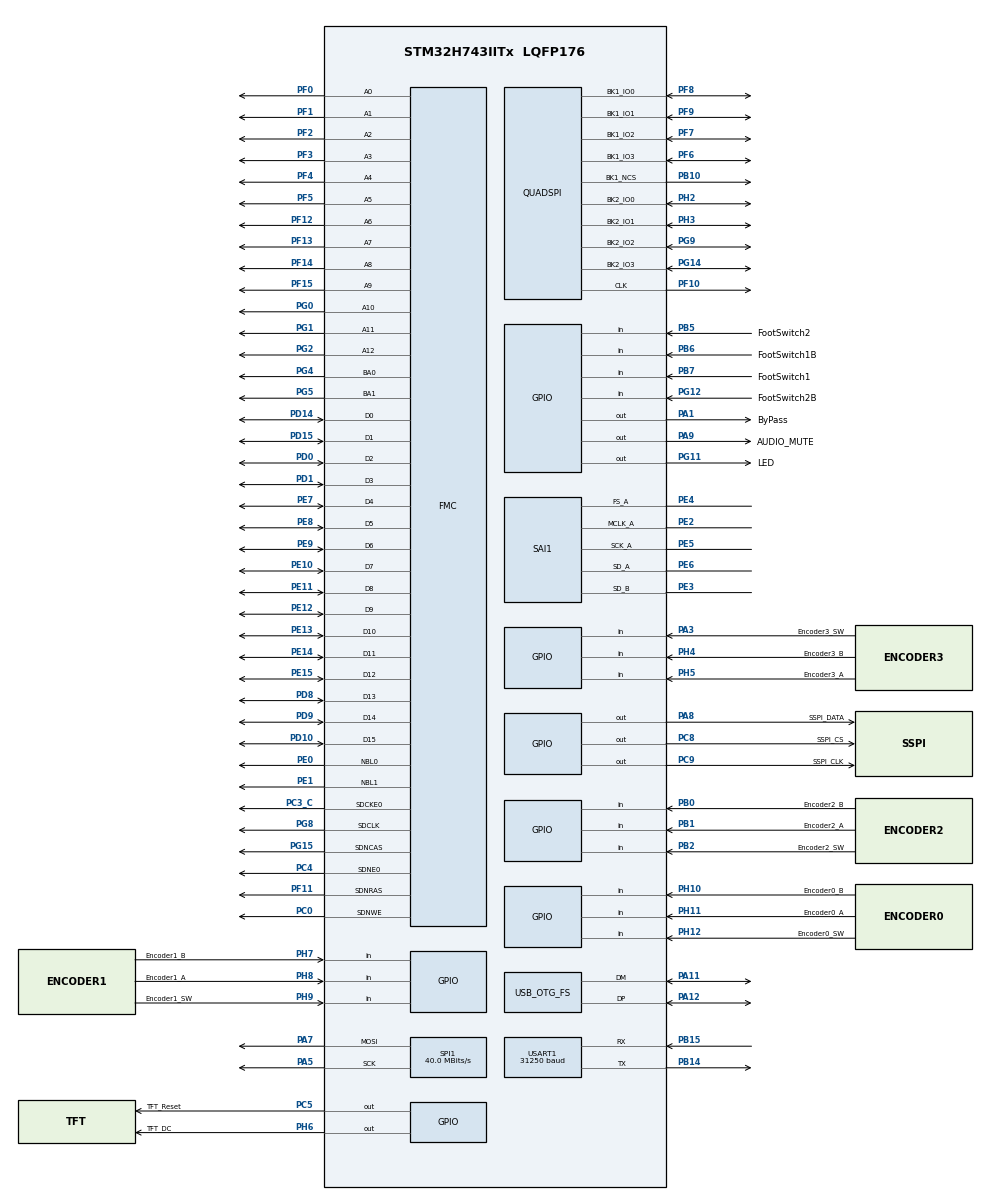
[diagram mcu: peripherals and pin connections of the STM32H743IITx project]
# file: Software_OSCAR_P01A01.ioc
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CORTEX_M7.MPU_Control=__NULL
CORTEX_M7.default_mode_Activation=1
Dma.Request0=SAI1_A
Dma.Request1=SAI1_B
Dma.Request2=SPI1_TX
Dma.Request3=USART1_RX
Dma.SAI1_A.0.Direction=DMA_MEMORY_TO_PERIPH
Dma.SAI1_A.0.EventEnable=DISABLE
Dma.SAI1_A.0.FIFOMode=DMA_FIFOMODE_DISABLE
Dma.SAI1_A.0.Instance=DMA1_Stream0
Dma.SAI1_A.0.MemDataAlignment=DMA_MDATAALIGN_WORD
Dma.SAI1_A.0.MemInc=DMA_MINC_ENABLE
Dma.SAI1_A.0.Mode=DMA_CIRCULAR
Dma.SAI1_A.0.PeriphDataAlignment=DMA_PDATAALIGN_WORD
Dma.SAI1_A.0.PeriphInc=DMA_PINC_DISABLE
Dma.SAI1_A.0.Polarity=HAL_DMAMUX_REQ_GEN_RISING
Dma.SAI1_A.0.Priority=DMA_PRIORITY_HIGH
Dma.SAI1_A.0.RequestNumber=1
Dma.SAI1_A.0.SignalID=NONE
Dma.SAI1_A.0.SyncEnable=DISABLE
Dma.SAI1_A.0.SyncPolarity=HAL_DMAMUX_SYNC_NO_EVENT
Dma.SAI1_A.0.SyncRequestNumber=1
Dma.SAI1_A.0.SyncSignalID=NONE
Dma.SAI1_B.1.Direction=DMA_PERIPH_TO_MEMORY
Dma.SAI1_B.1.EventEnable=DISABLE
Dma.SAI1_B.1.FIFOMode=DMA_FIFOMODE_DISABLE
Dma.SAI1_B.1.Instance=DMA1_Stream1
Dma.SAI1_B.1.MemDataAlignment=DMA_MDATAALIGN_WORD
Dma.SAI1_B.1.MemInc=DMA_MINC_ENABLE
Dma.SAI1_B.1.Mode=DMA_CIRCULAR
Dma.SAI1_B.1.PeriphDataAlignment=DMA_PDATAALIGN_WORD
Dma.SAI1_B.1.PeriphInc=DMA_PINC_DISABLE
Dma.SAI1_B.1.Polarity=HAL_DMAMUX_REQ_GEN_RISING
Dma.SAI1_B.1.Priority=DMA_PRIORITY_HIGH
Dma.SAI1_B.1.RequestNumber=1
Dma.SAI1_B.1.SignalID=NONE
Dma.SAI1_B.1.SyncEnable=DISABLE
Dma.SAI1_B.1.SyncPolarity=HAL_DMAMUX_SYNC_NO_EVENT
Dma.SAI1_B.1.SyncRequestNumber=1
Dma.SAI1_B.1.SyncSignalID=NONE
Dma.SPI1_TX.2.Direction=DMA_MEMORY_TO_PERIPH
Dma.SPI1_TX.2.EventEnable=DISABLE
Dma.SPI1_TX.2.FIFOMode=DMA_FIFOMODE_DISABLE
Dma.SPI1_TX.2.Instance=DMA1_Stream2
Dma.SPI1_TX.2.MemDataAlignment=DMA_MDATAALIGN_BYTE
Dma.SPI1_TX.2.MemInc=DMA_MINC_ENABLE
Dma.SPI1_TX.2.Mode=DMA_NORMAL
Dma.SPI1_TX.2.PeriphDataAlignment=DMA_PDATAALIGN_BYTE
Dma.SPI1_TX.2.PeriphInc=DMA_PINC_DISABLE
Dma.SPI1_TX.2.Polarity=HAL_DMAMUX_REQ_GEN_RISING
Dma.SPI1_TX.2.Priority=DMA_PRIORITY_MEDIUM
Dma.SPI1_TX.2.RequestNumber=1
Dma.SPI1_TX.2.SignalID=NONE
Dma.SPI1_TX.2.SyncEnable=DISABLE
Dma.SPI1_TX.2.SyncPolarity=HAL_DMAMUX_SYNC_NO_EVENT
Dma.SPI1_TX.2.SyncRequestNumber=1
Dma.SPI1_TX.2.SyncSignalID=NONE
Dma.USART1_RX.3.Direction=DMA_PERIPH_TO_MEMORY
Dma.USART1_RX.3.EventEnable=DISABLE
Dma.USART1_RX.3.FIFOMode=DMA_FIFOMODE_DISABLE
Dma.USART1_RX.3.Instance=DMA1_Stream3
Dma.USART1_RX.3.MemDataAlignment=DMA_MDATAALIGN_BYTE
Dma.USART1_RX.3.MemInc=DMA_MINC_ENABLE
Dma.USART1_RX.3.Mode=DMA_CIRCULAR
Dma.USART1_RX.3.PeriphDataAlignment=DMA_PDATAALIGN_BYTE
Dma.USART1_RX.3.PeriphInc=DMA_PINC_DISABLE
Dma.USART1_RX.3.Polarity=HAL_DMAMUX_REQ_GEN_RISING
Dma.USART1_RX.3.Priority=DMA_PRIORITY_LOW
Dma.USART1_RX.3.RequestNumber=1
Dma.USART1_RX.3.SignalID=NONE
Dma.USART1_RX.3.SyncEnable=DISABLE
Dma.USART1_RX.3.SyncPolarity=HAL_DMAMUX_SYNC_NO_EVENT
Dma.USART1_RX.3.SyncRequestNumber=1
Dma.USART1_RX.3.SyncSignalID=NONE
FMC.CASLatency1=FMC_SDRAM_CAS_LATENCY_2
FMC.ColumnBitsNumber1=FMC_SDRAM_COLUMN_BITS_NUM_10
FMC.ExitSelfRefreshDelay1=10
FMC.LoadToActiveDelay1=2
FMC.RCDDelay1=3
FMC.RPDelay1=3
FMC.RPDelay2=3
FMC.ReadBurst1=FMC_SDRAM_RBURST_ENABLE
FMC.ReadBurst2=FMC_SDRAM_RBURST_ENABLE
FMC.ReadPipeDelay1=FMC_SDRAM_RPIPE_DELAY_0
FMC.RowCycleDelay1=10
FMC.RowCycleDelay2=10
FMC.SDClockPeriod1=FMC_SDRAM_CLOCK_PERIOD_2
FMC.SDClockPeriod2=FMC_SDRAM_CLOCK_PERIOD_2
FMC.SelfRefreshTime1=7
FMC.WriteRecoveryTime1=4
Mcu.Family=STM32H7
Mcu.Name=STM32H743IITx
Mcu.Package=LQFP176
NVIC.DMA1_Stream0_IRQn=true\:0\:0\:false\:false\:true\:false\:true\:true
NVIC.DMA1_Stream1_IRQn=true\:0\:0\:false\:false\:true\:false\:true\:true
NVIC.DMA1_Stream2_IRQn=true\:0\:0\:false\:false\:true\:false\:true\:true
NVIC.DMA1_Stream3_IRQn=true\:0\:0\:false\:false\:true\:false\:true\:true
NVIC.OTG_FS_IRQn=true\:0\:0\:false\:false\:true\:false\:true\:true
NVIC.PriorityGroup=NVIC_PRIORITYGROUP_4
NVIC.SPI1_IRQn=true\:0\:0\:false\:false\:true\:false\:true\:true
NVIC.TIM6_DAC_IRQn=true\:0\:0\:false\:false\:true\:true\:true\:true
PA1.GPIO_Label=ByPass
PA1.Signal=GPIO_Output
PA11.Mode=Device_Only
PA11.Signal=USB_OTG_FS_DM
PA12.Mode=Device_Only
PA12.Signal=USB_OTG_FS_DP
PA13\ (JTMS/SWDIO).Mode=Serial_Wire
PA13\ (JTMS/SWDIO).Signal=DEBUG_JTMS-SWDIO
PA14\ (JTCK/SWCLK).Mode=Serial_Wire
PA14\ (JTCK/SWCLK).Signal=DEBUG_JTCK-SWCLK
PA3.GPIO_Label=Encoder3_SW
PA3.GPIO_PuPd=GPIO_PULLUP
PA3.Signal=GPIO_Input
PA5.GPIO_Speed=GPIO_SPEED_FREQ_HIGH
PA5.Mode=TX_Only_Simplex_Unidirect_Master
PA5.Signal=SPI1_SCK
PA7.GPIO_Speed=GPIO_SPEED_FREQ_HIGH
PA7.Mode=TX_Only_Simplex_Unidirect_Master
PA7.Signal=SPI1_MOSI
PA8.GPIO_Label=SSPI_DATA
PA8.GPIO_ModeDefaultOutputPP=GPIO_MODE_OUTPUT_OD
PA8.GPIO_PuPd=GPIO_NOPULL
PA8.GPIO_Speed=GPIO_SPEED_FREQ_HIGH
PA8.Signal=GPIO_Output
PA9.GPIO_Label=AUDIO_MUTE
PA9.GPIO_ModeDefaultOutputPP=GPIO_MODE_OUTPUT_OD
PA9.GPIO_PuPd=GPIO_NOPULL
PA9.Signal=GPIO_Output
PB0.GPIO_Label=Encoder2_B
PB0.GPIO_PuPd=GPIO_PULLUP
PB0.Signal=GPIO_Input
PB1.GPIO_Label=Encoder2_A
PB1.GPIO_PuPd=GPIO_PULLUP
PB1.Signal=GPIO_Input
PB10.GPIO_Speed=GPIO_SPEED_FREQ_VERY_HIGH
PB10.Mode=Enable Chip Select 1 for both banks
PB10.Signal=QUADSPI_BK1_NCS
PB14.Mode=Asynchronous
PB14.Signal=USART1_TX
PB15.Mode=Asynchronous
PB15.Signal=USART1_RX
PB2.GPIO_Label=Encoder2_SW
PB2.GPIO_PuPd=GPIO_PULLUP
PB2.Signal=GPIO_Input
PB5.GPIO_Label=FootSwitch2
PB5.GPIO_PuPd=GPIO_PULLUP
PB5.Signal=GPIO_Input
PB6.GPIO_Label=FootSwitch1B
PB6.GPIO_PuPd=GPIO_PULLUP
PB6.Signal=GPIO_Input
PB7.GPIO_Label=FootSwitch1
PB7.GPIO_PuPd=GPIO_PULLUP
PB7.Signal=GPIO_Input
PC0.Signal=FMC_SDNWE
PC3_C.Mode=SdramChipSelect1_1
PC3_C.Signal=FMC_SDCKE0
PC4.Mode=SdramChipSelect1_1
PC4.Signal=FMC_SDNE0
PC5.GPIO_Label=TFT_Reset
PC5.GPIO_Speed=GPIO_SPEED_FREQ_MEDIUM
PC5.Signal=GPIO_Output
PC8.GPIO_Label=SSPI_CS
PC8.GPIO_ModeDefaultOutputPP=GPIO_MODE_OUTPUT_OD
PC8.GPIO_PuPd=GPIO_NOPULL
PC8.GPIO_Speed=GPIO_SPEED_FREQ_HIGH
PC8.Signal=GPIO_Output
PC9.GPIO_Label=SSPI_CLK
PC9.GPIO_ModeDefaultOutputPP=GPIO_MODE_OUTPUT_OD
PC9.GPIO_PuPd=GPIO_NOPULL
PC9.GPIO_Speed=GPIO_SPEED_FREQ_HIGH
PC9.Signal=GPIO_Output
PD0.Signal=FMC_D2_DA2
PD1.Signal=FMC_D3_DA3
PD10.Signal=FMC_D15_DA15
PD14.Signal=FMC_D0_DA0
PD15.Signal=FMC_D1_DA1
PD8.Signal=FMC_D13_DA13
PD9.Signal=FMC_D14_DA14
PE0.Signal=FMC_NBL0
PE1.Signal=FMC_NBL1
PE10.Signal=FMC_D7_DA7
PE11.Signal=FMC_D8_DA8
PE12.Signal=FMC_D9_DA9
PE13.Signal=FMC_D10_DA10
PE14.Signal=FMC_D11_DA11
PE15.Signal=FMC_D12_DA12
PE2.Mode=SAI_A_MasterWithClock
PE2.Signal=SAI1_MCLK_A
PE3.Mode=SAI_B_SyncSlave
PE3.Signal=SAI1_SD_B
PE4.Mode=SAI_A_MasterWithClock
PE4.Signal=SAI1_FS_A
PE5.Mode=SAI_A_MasterWithClock
PE5.Signal=SAI1_SCK_A
PE6.Mode=SAI_A_MasterWithClock
PE6.Signal=SAI1_SD_A
PE7.Signal=FMC_D4_DA4
PE8.Signal=FMC_D5_DA5
PE9.Signal=FMC_D6_DA6
PF0.Signal=FMC_A0
PF1.Signal=FMC_A1
PF10.GPIO_Speed=GPIO_SPEED_FREQ_VERY_HIGH
PF10.Mode=Dual_Bank
PF10.Signal=QUADSPI_CLK
PF11.Signal=FMC_SDNRAS
PF12.Signal=FMC_A6
PF13.Signal=FMC_A7
PF14.Signal=FMC_A8
PF15.Signal=FMC_A9
PF2.Signal=FMC_A2
PF3.Signal=FMC_A3
PF4.Signal=FMC_A4
PF5.Signal=FMC_A5
PF6.GPIO_Speed=GPIO_SPEED_FREQ_VERY_HIGH
PF6.Mode=Dual_Bank
PF6.Signal=QUADSPI_BK1_IO3
PF7.GPIO_Speed=GPIO_SPEED_FREQ_VERY_HIGH
PF7.Mode=Dual_Bank
PF7.Signal=QUADSPI_BK1_IO2
PF8.GPIO_Speed=GPIO_SPEED_FREQ_VERY_HIGH
PF8.Mode=Dual_Bank
PF8.Signal=QUADSPI_BK1_IO0
PF9.GPIO_Speed=GPIO_SPEED_FREQ_VERY_HIGH
PF9.Mode=Dual_Bank
PF9.Signal=QUADSPI_BK1_IO1
PG0.Signal=FMC_A10
PG1.Signal=FMC_A11
PG11.GPIO_Label=LED
PG11.GPIO_ModeDefaultOutputPP=GPIO_MODE_OUTPUT_OD
PG11.GPIO_PuPd=GPIO_NOPULL
PG11.Signal=GPIO_Output
PG12.GPIO_Label=FootSwitch2B
PG12.GPIO_PuPd=GPIO_PULLUP
PG12.Signal=GPIO_Input
PG14.GPIO_Speed=GPIO_SPEED_FREQ_VERY_HIGH
PG14.Mode=Dual_Bank
PG14.Signal=QUADSPI_BK2_IO3
PG15.Signal=FMC_SDNCAS
PG2.Signal=FMC_A12
PG4.Signal=FMC_A14_BA0
PG5.Signal=FMC_A15_BA1
PG8.Signal=FMC_SDCLK
PG9.GPIO_Speed=GPIO_SPEED_FREQ_VERY_HIGH
PG9.Mode=Dual_Bank
PG9.Signal=QUADSPI_BK2_IO2
PH0-OSC_IN\ (PH0).Mode=HSE-External-Oscillator
PH0-OSC_IN\ (PH0).Signal=RCC_OSC_IN
PH1-OSC_OUT\ (PH1).Mode=HSE-External-Oscillator
PH1-OSC_OUT\ (PH1).Signal=RCC_OSC_OUT
PH10.GPIO_Label=Encoder0_B
PH10.GPIO_PuPd=GPIO_PULLUP
PH10.Signal=GPIO_Input
PH11.GPIO_Label=Encoder0_A
PH11.GPIO_PuPd=GPIO_PULLUP
PH11.Signal=GPIO_Input
PH12.GPIO_Label=Encoder0_SW
PH12.GPIO_PuPd=GPIO_PULLUP
PH12.Signal=GPIO_Input
PH2.GPIO_Speed=GPIO_SPEED_FREQ_VERY_HIGH
PH2.Mode=Dual_Bank
PH2.Signal=QUADSPI_BK2_IO0
PH3.GPIO_Speed=GPIO_SPEED_FREQ_VERY_HIGH
PH3.Mode=Dual_Bank
PH3.Signal=QUADSPI_BK2_IO1
PH4.GPIO_Label=Encoder3_B
PH4.GPIO_PuPd=GPIO_PULLUP
PH4.Signal=GPIO_Input
PH5.GPIO_Label=Encoder3_A
PH5.GPIO_PuPd=GPIO_PULLUP
PH5.Signal=GPIO_Input
PH6.GPIO_Label=TFT_DC
PH6.GPIO_Speed=GPIO_SPEED_FREQ_HIGH
PH6.Signal=GPIO_Output
PH7.GPIO_Label=Encoder1_B
PH7.GPIO_PuPd=GPIO_PULLUP
PH7.Signal=GPIO_Input
PH8.GPIO_Label=Encoder1_A
PH8.GPIO_PuPd=GPIO_PULLUP
PH8.Signal=GPIO_Input
PH9.GPIO_Label=Encoder1_SW
PH9.GPIO_PuPd=GPIO_PULLUP
PH9.Signal=GPIO_Input
ProjectManager.HeapSize=0x8000
ProjectManager.StackSize=0x2000
ProjectManager.TargetToolchain=STM32CubeIDE
QUADSPI.ChipSelectHighTime=QSPI_CS_HIGH_TIME_1_CYCLE
QUADSPI.ClockPrescaler=2
QUADSPI.FlashSize=24
QUADSPI.SampleShifting=QSPI_SAMPLE_SHIFTING_HALFCYCLE
RCC.ADCFreq_Value=185000000
RCC.APB1Freq_Value=120000000
RCC.APB2Freq_Value=120000000
RCC.APB3Freq_Value=120000000
RCC.APB4Freq_Value=120000000
RCC.CortexFreq_Value=480000000
RCC.D1PPRE=RCC_APB3_DIV2
RCC.D2PPRE1=RCC_APB1_DIV2
RCC.D2PPRE2=RCC_APB2_DIV2
RCC.D3PPRE=RCC_APB4_DIV2
RCC.DIVM1=5
RCC.DIVM2=10
RCC.DIVM3=3
RCC.DIVN1=192
RCC.DIVN2=148
RCC.DIVN3=48
RCC.DIVP3=33
RCC.DIVQ1=6
RCC.DIVQ3=3
RCC.DIVR1=8
RCC.FMCCLockSelection=RCC_FMCCLKSOURCE_PLL2
RCC.HCLKFreq_Value=240000000
RCC.HPRE=RCC_HCLK_DIV2
RCC.PLL2FRACN=0
RCC.PLL3FRACN=5411
RCC.PLLSourceVirtual=RCC_PLLSOURCE_HSE
RCC.SAI1CLockSelection=RCC_SAI1CLKSOURCE_PLL3
RCC.SYSCLKFreq_VALUE=480000000
RCC.SYSCLKSource=RCC_SYSCLKSOURCE_PLLCLK
RCC.USBCLockSelection=RCC_USBCLKSOURCE_HSI48
RCC.USBFreq_Value=48000000
SAI1.AudioFrequency-SAI_A_MasterWithClock=SAI_AUDIO_FREQUENCY_48K
SAI1.BasicDataSize-SAI_A_MasterWithClock=SAI_PROTOCOL_DATASIZE_24BIT
SAI1.BasicDataSize-SAI_B_SyncSlave=SAI_PROTOCOL_DATASIZE_24BIT
SAI1.BasicProtocol-SAI_A_MasterWithClock=SAI_I2S_MSBJUSTIFIED
SAI1.BasicProtocol-SAI_B_SyncSlave=SAI_I2S_MSBJUSTIFIED
SAI1.ErrorAudioFreq-SAI_A_MasterWithClock=0.0 %
SAI1.InitProtocol-SAI_A_MasterWithClock=Enable
SAI1.InitProtocol-SAI_B_SyncSlave=Enable
SAI1.Instance-SAI_A_MasterWithClock=SAI$Index_Block_A
SAI1.Instance-SAI_B_SyncSlave=SAI$Index_Block_B
SAI1.MClockEnable-SAI_A_MasterWithClock=SAI_MASTERCLOCK_ENABLE
SAI1.RealAudioFreq-SAI_A_MasterWithClock=48.0 KHz
SAI1.VirtualMode-SAI_A_MasterWithClock=VM_MASTER
SAI1.VirtualMode-SAI_B_SyncSlave=VM_SLAVE
SAI1.VirtualProtocol-SAI_A_BASIC=VM_BASIC_PROTOCOL
SAI1.VirtualProtocol-SAI_B_BASIC=VM_BASIC_PROTOCOL
SH.FMC_A0.0=FMC_A0,13b-sda1
SH.FMC_A1.0=FMC_A1,13b-sda1
SH.FMC_A10.0=FMC_A10,13b-sda1
SH.FMC_A11.0=FMC_A11,13b-sda1
SH.FMC_A12.0=FMC_A12,13b-sda1
SH.FMC_A14_BA0.0=FMC_BA0,FourSdramBanks1
SH.FMC_A15_BA1.0=FMC_BA1,FourSdramBanks1
SH.FMC_A2.0=FMC_A2,13b-sda1
SH.FMC_A3.0=FMC_A3,13b-sda1
SH.FMC_A4.0=FMC_A4,13b-sda1
SH.FMC_A5.0=FMC_A5,13b-sda1
SH.FMC_A6.0=FMC_A6,13b-sda1
SH.FMC_A7.0=FMC_A7,13b-sda1
SH.FMC_A8.0=FMC_A8,13b-sda1
SH.FMC_A9.0=FMC_A9,13b-sda1
SH.FMC_D0_DA0.0=FMC_D0,sd-16b-d1
SH.FMC_D10_DA10.0=FMC_D10,sd-16b-d1
SH.FMC_D11_DA11.0=FMC_D11,sd-16b-d1
SH.FMC_D12_DA12.0=FMC_D12,sd-16b-d1
SH.FMC_D13_DA13.0=FMC_D13,sd-16b-d1
SH.FMC_D14_DA14.0=FMC_D14,sd-16b-d1
SH.FMC_D15_DA15.0=FMC_D15,sd-16b-d1
SH.FMC_D1_DA1.0=FMC_D1,sd-16b-d1
SH.FMC_D2_DA2.0=FMC_D2,sd-16b-d1
SH.FMC_D3_DA3.0=FMC_D3,sd-16b-d1
SH.FMC_D4_DA4.0=FMC_D4,sd-16b-d1
SH.FMC_D5_DA5.0=FMC_D5,sd-16b-d1
SH.FMC_D6_DA6.0=FMC_D6,sd-16b-d1
SH.FMC_D7_DA7.0=FMC_D7,sd-16b-d1
SH.FMC_D8_DA8.0=FMC_D8,sd-16b-d1
SH.FMC_D9_DA9.0=FMC_D9,sd-16b-d1
SH.FMC_NBL0.0=FMC_NBL0,Sd2ByteEnable1
SH.FMC_NBL1.0=FMC_NBL1,Sd2ByteEnable1
SH.FMC_SDCLK.0=FMC_SDCLK,13b-sda1
SH.FMC_SDNCAS.0=FMC_SDNCAS,13b-sda1
SH.FMC_SDNRAS.0=FMC_SDNRAS,13b-sda1
SH.FMC_SDNWE.0=FMC_SDNWE,13b-sda1
SPI1.BaudRatePrescaler=SPI_BAUDRATEPRESCALER_4
SPI1.CLKPhase=SPI_PHASE_2EDGE
SPI1.CLKPolarity=SPI_POLARITY_HIGH
SPI1.CalculateBaudRate=40.0 MBits/s
SPI1.DataSize=SPI_DATASIZE_8BIT
SPI1.Direction=SPI_DIRECTION_2LINES_TXONLY
SPI1.MasterKeepIOState=SPI_MASTER_KEEP_IO_STATE_ENABLE
SPI1.Mode=SPI_MODE_MASTER
SPI1.VirtualType=VM_MASTER
TIM6.AutoReloadPreload=TIM_AUTORELOAD_PRELOAD_ENABLE
TIM6.Period=40-1
TIM6.Prescaler=100-1
USART1.BaudRate=31250
USART1.Mode=MODE_RX
USART1.VirtualMode-Asynchronous=VM_ASYNC
USB_DEVICE.CLASS_NAME_FS=CDC
USB_DEVICE.VirtualMode-CDC_FS=Cdc
USB_DEVICE.VirtualModeFS=Cdc_FS
USB_OTG_FS.VirtualMode=Device_Only
VP_DMA2D_VS_DMA2D.Mode=DMA2D_Activate
VP_MEMORYMAP_VS_MEMORYMAP.Mode=CurAppReg
VP_RNG_VS_RNG.Mode=RNG_Activate
VP_SAI1_VP_$IpInstance_SAIA_SAI_BASIC.Mode=SAI_A_BASIC
VP_SAI1_VP_$IpInstance_SAIB_SAI_BASIC.Mode=SAI_B_BASIC
VP_TIM6_VS_ClockSourceINT.Mode=Enable_Timer
VP_USB_DEVICE_VS_USB_DEVICE_CDC_FS.Mode=CDC_FS
board=custom

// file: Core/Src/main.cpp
/* USER CODE BEGIN Header */
/**
  ******************************************************************************
  * @file           : main.c
  * @brief          : Main program body
  ******************************************************************************
  * @attention
  *
  * Copyright (c) 2026 STMicroelectronics.
  * All rights reserved.
  *
  * This software is licensed under terms that can be found in the LICENSE file
  * in the root directory of this software component.
  * If no LICENSE file comes with this software, it is provided AS-IS.
  *
  ******************************************************************************
  */
/* USER CODE END Header */
#include "main.h"
#include "usb_device.h"

DMA2D_HandleTypeDef hdma2d;

QSPI_HandleTypeDef hqspi;

RNG_HandleTypeDef hrng;

SAI_HandleTypeDef hsai_BlockA1;
SAI_HandleTypeDef hsai_BlockB1;
DMA_HandleTypeDef hdma_sai1_a;
DMA_HandleTypeDef hdma_sai1_b;

SPI_HandleTypeDef hspi1;
DMA_HandleTypeDef hdma_spi1_tx;

TIM_HandleTypeDef htim6;

UART_HandleTypeDef huart1;
DMA_HandleTypeDef hdma_usart1_rx;

SDRAM_HandleTypeDef hsdram1;

void SystemClock_Config(void);
void PeriphCommonClock_Config(void);
static void MX_RNG_Init(void);
/* USER CODE BEGIN PFP */

	// =====** DAD **=================================================================

	extern void HardwareAndCoInitialize();

	// ===** END DAD **===============================================================

/* USER CODE END PFP */

int main(void)
{

  /* USER CODE BEGIN 1 */
	// =====** DAD **=================================================================

	#ifdef USE_RAM
	SCB->VTOR = 0x24000000;
	#endif

	// ===** END DAD **===============================================================

  /* USER CODE END 1 */

  /* MCU Configuration--------------------------------------------------------*/

  /* Reset of all peripherals, Initializes the Flash interface and the Systick. */
  HAL_Init();

  /* USER CODE BEGIN Init */

	// =====** DAD **=================================================================

	// *** LA LIGNE MAGIQUE ***
	// Modifie le registre FPSCR (Floating Point Status and Control Register)
	// Bit 24 (FZ) : Flush-to-zero mode enable
	// Bit 25 (DN) : Default NaN mode enable
	__set_FPSCR(__get_FPSCR() | (1<<24) | (1<<25));

	// ===** END DAD **===============================================================

  /* USER CODE END Init */

  /* Configure the system clock */
  SystemClock_Config();

  /* Configure the peripherals common clocks */
  PeriphCommonClock_Config();

  /* Initialize all configured peripherals */
  MX_GPIO_Init();
  MX_DMA_Init();
  MX_FMC_Init();
  MX_QUADSPI_Init();
  MX_SAI1_Init();
  MX_SPI1_Init();
  MX_USART1_UART_Init();
  MX_TIM6_Init();
  MX_DMA2D_Init();
  MX_USB_DEVICE_Init();
  MX_RNG_Init();
  /* USER CODE BEGIN 2 */

	// =====** DAD **=================================================================

	HardwareAndCoInitialize();

	// ===** END DAD **===============================================================

  /* USER CODE END 2 */

  /* Infinite loop */
  while (1)
  {

  }
}

void SystemClock_Config(void)
{
  RCC_OscInitTypeDef RCC_OscInitStruct = {0};
  RCC_ClkInitTypeDef RCC_ClkInitStruct = {0};

  /** Supply configuration update enable
  */
  HAL_PWREx_ConfigSupply(PWR_LDO_SUPPLY);

  /** Configure the main internal regulator output voltage
  */
  __HAL_PWR_VOLTAGESCALING_CONFIG(PWR_REGULATOR_VOLTAGE_SCALE0);

  while(!__HAL_PWR_GET_FLAG(PWR_FLAG_VOSRDY)) {}

  /** Initializes the RCC Oscillators according to the specified parameters
  * in the RCC_OscInitTypeDef structure.
  */
  RCC_OscInitStruct.OscillatorType = RCC_OSCILLATORTYPE_HSI48|RCC_OSCILLATORTYPE_HSE;
  RCC_OscInitStruct.HSEState = RCC_HSE_ON;
  RCC_OscInitStruct.HSI48State = RCC_HSI48_ON;
  RCC_OscInitStruct.PLL.PLLState = RCC_PLL_ON;
  RCC_OscInitStruct.PLL.PLLSource = RCC_PLLSOURCE_HSE;
  RCC_OscInitStruct.PLL.PLLM = 5;
  RCC_OscInitStruct.PLL.PLLN = 192;
  RCC_OscInitStruct.PLL.PLLP = 2;
  RCC_OscInitStruct.PLL.PLLQ = 6;
  RCC_OscInitStruct.PLL.PLLR = 8;
  RCC_OscInitStruct.PLL.PLLRGE = RCC_PLL1VCIRANGE_2;
  RCC_OscInitStruct.PLL.PLLVCOSEL = RCC_PLL1VCOWIDE;
  RCC_OscInitStruct.PLL.PLLFRACN = 0;
  if (HAL_RCC_OscConfig(&RCC_OscInitStruct) != HAL_OK)
  {
    Error_Handler();
  }

  /** Initializes the CPU, AHB and APB buses clocks
  */
  RCC_ClkInitStruct.ClockType = RCC_CLOCKTYPE_HCLK|RCC_CLOCKTYPE_SYSCLK
                              |RCC_CLOCKTYPE_PCLK1|RCC_CLOCKTYPE_PCLK2
                              |RCC_CLOCKTYPE_D3PCLK1|RCC_CLOCKTYPE_D1PCLK1;
  RCC_ClkInitStruct.SYSCLKSource = RCC_SYSCLKSOURCE_PLLCLK;
  RCC_ClkInitStruct.SYSCLKDivider = RCC_SYSCLK_DIV1;
  RCC_ClkInitStruct.AHBCLKDivider = RCC_HCLK_DIV2;
  RCC_ClkInitStruct.APB3CLKDivider = RCC_APB3_DIV2;
  RCC_ClkInitStruct.APB1CLKDivider = RCC_APB1_DIV2;
  RCC_ClkInitStruct.APB2CLKDivider = RCC_APB2_DIV2;
  RCC_ClkInitStruct.APB4CLKDivider = RCC_APB4_DIV2;

  if (HAL_RCC_ClockConfig(&RCC_ClkInitStruct, FLASH_LATENCY_4) != HAL_OK)
  {
    Error_Handler();
  }
}

void PeriphCommonClock_Config(void)
{
  RCC_PeriphCLKInitTypeDef PeriphClkInitStruct = {0};

  /** Initializes the peripherals clock
  */
  PeriphClkInitStruct.PeriphClockSelection = RCC_PERIPHCLK_SAI1;
  PeriphClkInitStruct.PLL3.PLL3M = 3;
  PeriphClkInitStruct.PLL3.PLL3N = 48;
  PeriphClkInitStruct.PLL3.PLL3P = 33;
  PeriphClkInitStruct.PLL3.PLL3Q = 3;
  PeriphClkInitStruct.PLL3.PLL3R = 2;
  PeriphClkInitStruct.PLL3.PLL3RGE = RCC_PLL3VCIRANGE_3;
  PeriphClkInitStruct.PLL3.PLL3VCOSEL = RCC_PLL3VCOWIDE;
  PeriphClkInitStruct.PLL3.PLL3FRACN = 5411;
  PeriphClkInitStruct.Sai1ClockSelection = RCC_SAI1CLKSOURCE_PLL3;
  if (HAL_RCCEx_PeriphCLKConfig(&PeriphClkInitStruct) != HAL_OK)
  {
    Error_Handler();
  }
}

void MX_DMA2D_Init(void)
{

  hdma2d.Instance = DMA2D;
  hdma2d.Init.Mode = DMA2D_M2M;
  hdma2d.Init.ColorMode = DMA2D_OUTPUT_ARGB8888;
  hdma2d.Init.OutputOffset = 0;
  hdma2d.LayerCfg[1].InputOffset = 0;
  hdma2d.LayerCfg[1].InputColorMode = DMA2D_INPUT_ARGB8888;
  hdma2d.LayerCfg[1].AlphaMode = DMA2D_NO_MODIF_ALPHA;
  hdma2d.LayerCfg[1].InputAlpha = 0;
  hdma2d.LayerCfg[1].AlphaInverted = DMA2D_REGULAR_ALPHA;
  hdma2d.LayerCfg[1].RedBlueSwap = DMA2D_RB_REGULAR;
  hdma2d.LayerCfg[1].ChromaSubSampling = DMA2D_NO_CSS;
  if (HAL_DMA2D_Init(&hdma2d) != HAL_OK)
  {
    Error_Handler();
  }
  if (HAL_DMA2D_ConfigLayer(&hdma2d, 1) != HAL_OK)
  {
    Error_Handler();
  }

}

void MX_QUADSPI_Init(void)
{

  /* QUADSPI parameter configuration*/
  hqspi.Instance = QUADSPI;
  hqspi.Init.ClockPrescaler = 2;
  hqspi.Init.FifoThreshold = 1;
  hqspi.Init.SampleShifting = QSPI_SAMPLE_SHIFTING_HALFCYCLE;
  hqspi.Init.FlashSize = 24;
  hqspi.Init.ChipSelectHighTime = QSPI_CS_HIGH_TIME_1_CYCLE;
  hqspi.Init.ClockMode = QSPI_CLOCK_MODE_0;
  hqspi.Init.DualFlash = QSPI_DUALFLASH_ENABLE;
  if (HAL_QSPI_Init(&hqspi) != HAL_OK)
  {
    Error_Handler();
  }

}

static void MX_RNG_Init(void)
{

  hrng.Instance = RNG;
  hrng.Init.ClockErrorDetection = RNG_CED_ENABLE;
  if (HAL_RNG_Init(&hrng) != HAL_OK)
  {
    Error_Handler();
  }

}

void MX_SAI1_Init(void)
{

  hsai_BlockA1.Instance = SAI1_Block_A;
  hsai_BlockA1.Init.AudioMode = SAI_MODEMASTER_TX;
  hsai_BlockA1.Init.Synchro = SAI_ASYNCHRONOUS;
  hsai_BlockA1.Init.OutputDrive = SAI_OUTPUTDRIVE_DISABLE;
  hsai_BlockA1.Init.NoDivider = SAI_MCK_OVERSAMPLING_DISABLE;
  hsai_BlockA1.Init.MckOverSampling = SAI_MCK_OVERSAMPLING_DISABLE;
  hsai_BlockA1.Init.FIFOThreshold = SAI_FIFOTHRESHOLD_EMPTY;
  hsai_BlockA1.Init.AudioFrequency = SAI_AUDIO_FREQUENCY_48K;
  hsai_BlockA1.Init.SynchroExt = SAI_SYNCEXT_DISABLE;
  hsai_BlockA1.Init.MonoStereoMode = SAI_STEREOMODE;
  hsai_BlockA1.Init.CompandingMode = SAI_NOCOMPANDING;
  hsai_BlockA1.Init.TriState = SAI_OUTPUT_NOTRELEASED;
  if (HAL_SAI_InitProtocol(&hsai_BlockA1, SAI_I2S_MSBJUSTIFIED, SAI_PROTOCOL_DATASIZE_24BIT, 2) != HAL_OK)
  {
    Error_Handler();
  }
  hsai_BlockB1.Instance = SAI1_Block_B;
  hsai_BlockB1.Init.AudioMode = SAI_MODESLAVE_RX;
  hsai_BlockB1.Init.Synchro = SAI_SYNCHRONOUS;
  hsai_BlockB1.Init.OutputDrive = SAI_OUTPUTDRIVE_DISABLE;
  hsai_BlockB1.Init.MckOverSampling = SAI_MCK_OVERSAMPLING_DISABLE;
  hsai_BlockB1.Init.FIFOThreshold = SAI_FIFOTHRESHOLD_EMPTY;
  hsai_BlockB1.Init.SynchroExt = SAI_SYNCEXT_DISABLE;
  hsai_BlockB1.Init.MonoStereoMode = SAI_STEREOMODE;
  hsai_BlockB1.Init.CompandingMode = SAI_NOCOMPANDING;
  hsai_BlockB1.Init.TriState = SAI_OUTPUT_NOTRELEASED;
  if (HAL_SAI_InitProtocol(&hsai_BlockB1, SAI_I2S_MSBJUSTIFIED, SAI_PROTOCOL_DATASIZE_24BIT, 2) != HAL_OK)
  {
    Error_Handler();
  }

}

void MX_SPI1_Init(void)
{

  /* SPI1 parameter configuration*/
  hspi1.Instance = SPI1;
  hspi1.Init.Mode = SPI_MODE_MASTER;
  hspi1.Init.Direction = SPI_DIRECTION_2LINES_TXONLY;
  hspi1.Init.DataSize = SPI_DATASIZE_8BIT;
  hspi1.Init.CLKPolarity = SPI_POLARITY_HIGH;
  hspi1.Init.CLKPhase = SPI_PHASE_2EDGE;
  hspi1.Init.NSS = SPI_NSS_SOFT;
  hspi1.Init.BaudRatePrescaler = SPI_BAUDRATEPRESCALER_4;
  hspi1.Init.FirstBit = SPI_FIRSTBIT_MSB;
  hspi1.Init.TIMode = SPI_TIMODE_DISABLE;
  hspi1.Init.CRCCalculation = SPI_CRCCALCULATION_DISABLE;
  hspi1.Init.CRCPolynomial = 0x0;
  hspi1.Init.NSSPMode = SPI_NSS_PULSE_ENABLE;
  hspi1.Init.NSSPolarity = SPI_NSS_POLARITY_LOW;
  hspi1.Init.FifoThreshold = SPI_FIFO_THRESHOLD_01DATA;
  hspi1.Init.TxCRCInitializationPattern = SPI_CRC_INITIALIZATION_ALL_ZERO_PATTERN;
  hspi1.Init.RxCRCInitializationPattern = SPI_CRC_INITIALIZATION_ALL_ZERO_PATTERN;
  hspi1.Init.MasterSSIdleness = SPI_MASTER_SS_IDLENESS_00CYCLE;
  hspi1.Init.MasterInterDataIdleness = SPI_MASTER_INTERDATA_IDLENESS_00CYCLE;
  hspi1.Init.MasterReceiverAutoSusp = SPI_MASTER_RX_AUTOSUSP_DISABLE;
  hspi1.Init.MasterKeepIOState = SPI_MASTER_KEEP_IO_STATE_ENABLE;
  hspi1.Init.IOSwap = SPI_IO_SWAP_DISABLE;
  if (HAL_SPI_Init(&hspi1) != HAL_OK)
  {
    Error_Handler();
  }

}

void MX_TIM6_Init(void)
{

  TIM_MasterConfigTypeDef sMasterConfig = {0};

  htim6.Instance = TIM6;
  htim6.Init.Prescaler = 100-1;
  htim6.Init.CounterMode = TIM_COUNTERMODE_UP;
  htim6.Init.Period = 40-1;
  htim6.Init.AutoReloadPreload = TIM_AUTORELOAD_PRELOAD_ENABLE;
  if (HAL_TIM_Base_Init(&htim6) != HAL_OK)
  {
    Error_Handler();
  }
  sMasterConfig.MasterOutputTrigger = TIM_TRGO_RESET;
  sMasterConfig.MasterSlaveMode = TIM_MASTERSLAVEMODE_DISABLE;
  if (HAL_TIMEx_MasterConfigSynchronization(&htim6, &sMasterConfig) != HAL_OK)
  {
    Error_Handler();
  }

}

void MX_USART1_UART_Init(void)
{

  huart1.Instance = USART1;
  huart1.Init.BaudRate = 31250;
  huart1.Init.WordLength = UART_WORDLENGTH_8B;
  huart1.Init.StopBits = UART_STOPBITS_1;
  huart1.Init.Parity = UART_PARITY_NONE;
  huart1.Init.Mode = UART_MODE_RX;
  huart1.Init.HwFlowCtl = UART_HWCONTROL_NONE;
  huart1.Init.OverSampling = UART_OVERSAMPLING_16;
  huart1.Init.OneBitSampling = UART_ONE_BIT_SAMPLE_DISABLE;
  huart1.Init.ClockPrescaler = UART_PRESCALER_DIV1;
  huart1.AdvancedInit.AdvFeatureInit = UART_ADVFEATURE_NO_INIT;
  if (HAL_UART_Init(&huart1) != HAL_OK)
  {
    Error_Handler();
  }
  if (HAL_UARTEx_SetTxFifoThreshold(&huart1, UART_TXFIFO_THRESHOLD_1_8) != HAL_OK)
  {
    Error_Handler();
  }
  if (HAL_UARTEx_SetRxFifoThreshold(&huart1, UART_RXFIFO_THRESHOLD_1_8) != HAL_OK)
  {
    Error_Handler();
  }
  if (HAL_UARTEx_DisableFifoMode(&huart1) != HAL_OK)
  {
    Error_Handler();
  }

}

void MX_DMA_Init(void)
{

  /* DMA controller clock enable */
  __HAL_RCC_DMA1_CLK_ENABLE();

  /* DMA interrupt init */
  /* DMA1_Stream0_IRQn interrupt configuration */
  HAL_NVIC_SetPriority(DMA1_Stream0_IRQn, 0, 0);
  HAL_NVIC_EnableIRQ(DMA1_Stream0_IRQn);
  /* DMA1_Stream1_IRQn interrupt configuration */
  HAL_NVIC_SetPriority(DMA1_Stream1_IRQn, 0, 0);
  HAL_NVIC_EnableIRQ(DMA1_Stream1_IRQn);
  /* DMA1_Stream2_IRQn interrupt configuration */
  HAL_NVIC_SetPriority(DMA1_Stream2_IRQn, 0, 0);
  HAL_NVIC_EnableIRQ(DMA1_Stream2_IRQn);
  /* DMA1_Stream3_IRQn interrupt configuration */
  HAL_NVIC_SetPriority(DMA1_Stream3_IRQn, 0, 0);
  HAL_NVIC_EnableIRQ(DMA1_Stream3_IRQn);

}

/* FMC initialization function */
void MX_FMC_Init(void)
{

  FMC_SDRAM_TimingTypeDef SdramTiming = {0};

  /** Perform the SDRAM1 memory initialization sequence
  */
  hsdram1.Instance = FMC_SDRAM_DEVICE;
  /* hsdram1.Init */
  hsdram1.Init.SDBank = FMC_SDRAM_BANK1;
  hsdram1.Init.ColumnBitsNumber = FMC_SDRAM_COLUMN_BITS_NUM_10;
  hsdram1.Init.RowBitsNumber = FMC_SDRAM_ROW_BITS_NUM_13;
  hsdram1.Init.MemoryDataWidth = FMC_SDRAM_MEM_BUS_WIDTH_16;
  hsdram1.Init.InternalBankNumber = FMC_SDRAM_INTERN_BANKS_NUM_4;
  hsdram1.Init.CASLatency = FMC_SDRAM_CAS_LATENCY_2;
  hsdram1.Init.WriteProtection = FMC_SDRAM_WRITE_PROTECTION_DISABLE;
  hsdram1.Init.SDClockPeriod = FMC_SDRAM_CLOCK_PERIOD_2;
  hsdram1.Init.ReadBurst = FMC_SDRAM_RBURST_ENABLE;
  hsdram1.Init.ReadPipeDelay = FMC_SDRAM_RPIPE_DELAY_0;
  /* SdramTiming */
  SdramTiming.LoadToActiveDelay = 2;
  SdramTiming.ExitSelfRefreshDelay = 10;
  SdramTiming.SelfRefreshTime = 7;
  SdramTiming.RowCycleDelay = 10;
  SdramTiming.WriteRecoveryTime = 4;
  SdramTiming.RPDelay = 3;
  SdramTiming.RCDDelay = 3;

  if (HAL_SDRAM_Init(&hsdram1, &SdramTiming) != HAL_OK)
  {
    Error_Handler( );
  }

}

void MX_GPIO_Init(void)
{
  GPIO_InitTypeDef GPIO_InitStruct = {0};

  /* GPIO Ports Clock Enable */
  __HAL_RCC_GPIOE_CLK_ENABLE();
  __HAL_RCC_GPIOF_CLK_ENABLE();
  __HAL_RCC_GPIOH_CLK_ENABLE();
  __HAL_RCC_GPIOC_CLK_ENABLE();
  __HAL_RCC_GPIOA_CLK_ENABLE();
  __HAL_RCC_GPIOB_CLK_ENABLE();
  __HAL_RCC_GPIOG_CLK_ENABLE();
  __HAL_RCC_GPIOD_CLK_ENABLE();

  /*Configure GPIO pin Output Level */
  HAL_GPIO_WritePin(GPIOA, ByPass_Pin|SSPI_DATA_Pin|AUDIO_MUTE_Pin, GPIO_PIN_RESET);

  /*Configure GPIO pin Output Level */
  HAL_GPIO_WritePin(GPIOC, TFT_Reset_Pin|SSPI_CS_Pin|SSPI_CLK_Pin, GPIO_PIN_RESET);

  /*Configure GPIO pin Output Level */
  HAL_GPIO_WritePin(TFT_DC_GPIO_Port, TFT_DC_Pin, GPIO_PIN_RESET);

  /*Configure GPIO pin Output Level */
  HAL_GPIO_WritePin(LED_GPIO_Port, LED_Pin, GPIO_PIN_RESET);

  /*Configure GPIO pin : ByPass_Pin */
  GPIO_InitStruct.Pin = ByPass_Pin;
  GPIO_InitStruct.Mode = GPIO_MODE_OUTPUT_PP;
  GPIO_InitStruct.Pull = GPIO_NOPULL;
  GPIO_InitStruct.Speed = GPIO_SPEED_FREQ_LOW;
  HAL_GPIO_Init(ByPass_GPIO_Port, &GPIO_InitStruct);

  /*Configure GPIO pins : Encoder3_B_Pin Encoder3_A_Pin Encoder1_B_Pin Encoder1_A_Pin
                           Encoder1_SW_Pin Encoder0_B_Pin Encoder0_A_Pin Encoder0_SW_Pin */
  GPIO_InitStruct.Pin = Encoder3_B_Pin|Encoder3_A_Pin|Encoder1_B_Pin|Encoder1_A_Pin
                          |Encoder1_SW_Pin|Encoder0_B_Pin|Encoder0_A_Pin|Encoder0_SW_Pin;
  GPIO_InitStruct.Mode = GPIO_MODE_INPUT;
  GPIO_InitStruct.Pull = GPIO_PULLUP;
  HAL_GPIO_Init(GPIOH, &GPIO_InitStruct);

  /*Configure GPIO pin : Encoder3_SW_Pin */
  GPIO_InitStruct.Pin = Encoder3_SW_Pin;
  GPIO_InitStruct.Mode = GPIO_MODE_INPUT;
  GPIO_InitStruct.Pull = GPIO_PULLUP;
  HAL_GPIO_Init(Encoder3_SW_GPIO_Port, &GPIO_InitStruct);

  /*Configure GPIO pin : TFT_Reset_Pin */
  GPIO_InitStruct.Pin = TFT_Reset_Pin;
  GPIO_InitStruct.Mode = GPIO_MODE_OUTPUT_PP;
  GPIO_InitStruct.Pull = GPIO_NOPULL;
  GPIO_InitStruct.Speed = GPIO_SPEED_FREQ_MEDIUM;
  HAL_GPIO_Init(TFT_Reset_GPIO_Port, &GPIO_InitStruct);

  /*Configure GPIO pins : Encoder2_B_Pin Encoder2_A_Pin Encoder2_SW_Pin FootSwitch2_Pin
                           FootSwitch1B_Pin FootSwitch1_Pin */
  GPIO_InitStruct.Pin = Encoder2_B_Pin|Encoder2_A_Pin|Encoder2_SW_Pin|FootSwitch2_Pin
                          |FootSwitch1B_Pin|FootSwitch1_Pin;
  GPIO_InitStruct.Mode = GPIO_MODE_INPUT;
  GPIO_InitStruct.Pull = GPIO_PULLUP;
  HAL_GPIO_Init(GPIOB, &GPIO_InitStruct);

  /*Configure GPIO pin : TFT_DC_Pin */
  GPIO_InitStruct.Pin = TFT_DC_Pin;
  GPIO_InitStruct.Mode = GPIO_MODE_OUTPUT_PP;
  GPIO_InitStruct.Pull = GPIO_NOPULL;
  GPIO_InitStruct.Speed = GPIO_SPEED_FREQ_HIGH;
  HAL_GPIO_Init(TFT_DC_GPIO_Port, &GPIO_InitStruct);

  /*Configure GPIO pins : SSPI_CS_Pin SSPI_CLK_Pin */
  GPIO_InitStruct.Pin = SSPI_CS_Pin|SSPI_CLK_Pin;
  GPIO_InitStruct.Mode = GPIO_MODE_OUTPUT_OD;
  GPIO_InitStruct.Pull = GPIO_NOPULL;
  GPIO_InitStruct.Speed = GPIO_SPEED_FREQ_HIGH;
  HAL_GPIO_Init(GPIOC, &GPIO_InitStruct);

  /*Configure GPIO pin : SSPI_DATA_Pin */
  GPIO_InitStruct.Pin = SSPI_DATA_Pin;
  GPIO_InitStruct.Mode = GPIO_MODE_OUTPUT_OD;
  GPIO_InitStruct.Pull = GPIO_NOPULL;
  GPIO_InitStruct.Speed = GPIO_SPEED_FREQ_HIGH;
  HAL_GPIO_Init(SSPI_DATA_GPIO_Port, &GPIO_InitStruct);

  /*Configure GPIO pin : AUDIO_MUTE_Pin */
  GPIO_InitStruct.Pin = AUDIO_MUTE_Pin;
  GPIO_InitStruct.Mode = GPIO_MODE_OUTPUT_OD;
  GPIO_InitStruct.Pull = GPIO_NOPULL;
  GPIO_InitStruct.Speed = GPIO_SPEED_FREQ_LOW;
  HAL_GPIO_Init(AUDIO_MUTE_GPIO_Port, &GPIO_InitStruct);

  /*Configure GPIO pin : LED_Pin */
  GPIO_InitStruct.Pin = LED_Pin;
  GPIO_InitStruct.Mode = GPIO_MODE_OUTPUT_OD;
  GPIO_InitStruct.Pull = GPIO_NOPULL;
  GPIO_InitStruct.Speed = GPIO_SPEED_FREQ_LOW;
  HAL_GPIO_Init(LED_GPIO_Port, &GPIO_InitStruct);

  /*Configure GPIO pin : FootSwitch2B_Pin */
  GPIO_InitStruct.Pin = FootSwitch2B_Pin;
  GPIO_InitStruct.Mode = GPIO_MODE_INPUT;
  GPIO_InitStruct.Pull = GPIO_PULLUP;
  HAL_GPIO_Init(FootSwitch2B_GPIO_Port, &GPIO_InitStruct);

  /*AnalogSwitch Config */
  HAL_SYSCFG_AnalogSwitchConfig(SYSCFG_SWITCH_PA1, SYSCFG_SWITCH_PA1_CLOSE);

}

void Error_Handler(void)
{
  __disable_irq();
  while (1)
  {
  }
}
